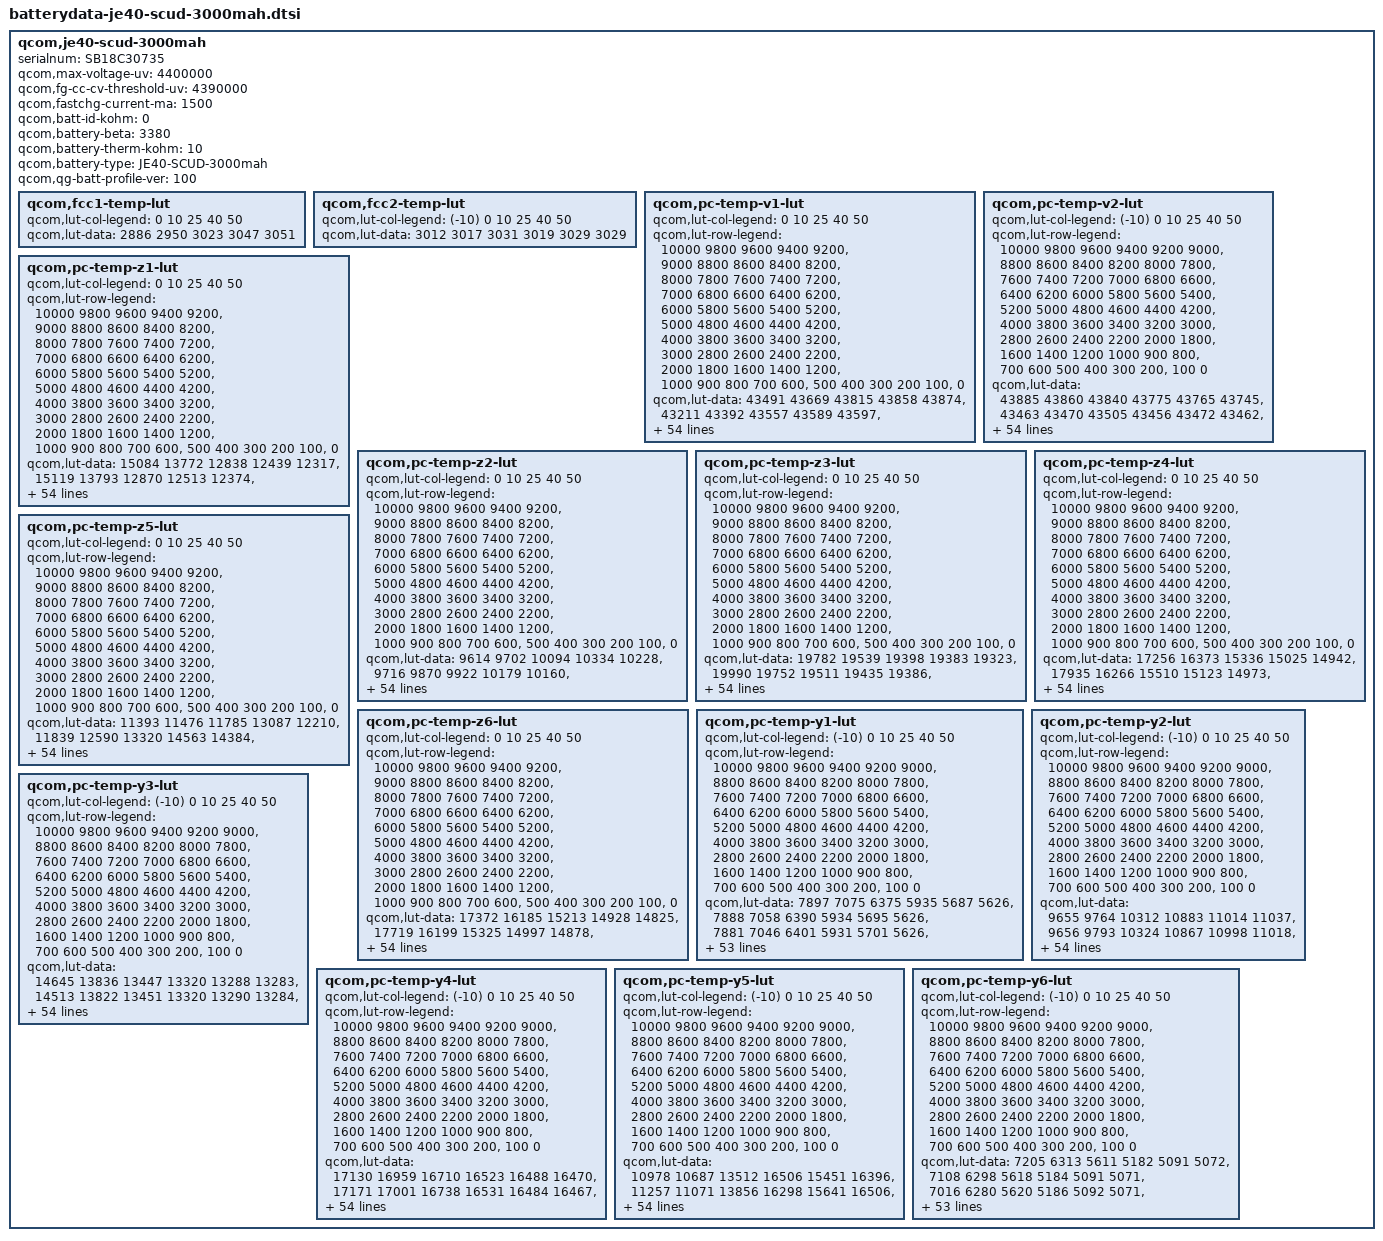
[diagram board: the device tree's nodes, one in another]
/* Copyright (c) 2018, The Linux Foundation. All rights reserved.
 *
 * This program is free software; you can redistribute it and/or modify
 * it under the terms of the GNU General Public License version 2 and
 * only version 2 as published by the Free Software Foundation.
 *
 * This program is distributed in the hope that it will be useful,
 * but WITHOUT ANY WARRANTY; without even the implied warranty of
 * MERCHANTABILITY or FITNESS FOR A PARTICULAR PURPOSE.  See the
 * GNU General Public License for more details.
 */

qcom,je40-scud-3000mah {
    serialnum = "SB18C30735";
    qcom,max-voltage-uv = <4400000>;
    qcom,fg-cc-cv-threshold-uv = <4390000>;
    qcom,fastchg-current-ma = <1500>;
    qcom,batt-id-kohm = <0>;
    qcom,battery-beta = <3380>;
    qcom,battery-therm-kohm = <10>;
    qcom,battery-type = "JE40-SCUD-3000mah";
    qcom,qg-batt-profile-ver = <100>;

	qcom,fcc1-temp-lut {
		qcom,lut-col-legend = <0 10 25 40 50>;
		qcom,lut-data = <2886 2950 3023 3047 3051>;
	};

        qcom,fcc2-temp-lut {
                qcom,lut-col-legend = <(-10) 0 10 25 40 50>;
                qcom,lut-data = <3012 3017 3031 3019 3029 3029>;
        };

	qcom,pc-temp-v1-lut {
		qcom,lut-col-legend = <0 10 25 40 50>;
		qcom,lut-row-legend = <10000 9800 9600 9400 9200>,
			<9000 8800 8600 8400 8200>,
			<8000 7800 7600 7400 7200>,
			<7000 6800 6600 6400 6200>,
			<6000 5800 5600 5400 5200>,
			<5000 4800 4600 4400 4200>,
			<4000 3800 3600 3400 3200>,
			<3000 2800 2600 2400 2200>,
			<2000 1800 1600 1400 1200>,
			<1000 900 800 700 600>,
			<500 400 300 200 100>,
			<0>;
		qcom,lut-data = <43491 43669 43815 43858 43874>,
			<43211 43392 43557 43589 43597>,
			<42956 43131 43303 43343 43353>,
			<42714 42886 43053 43104 43118>,
			<42476 42648 42808 42865 42880>,
			<42242 42411 42566 42626 42642>,
			<42016 42179 42328 42390 42407>,
			<41797 41952 42092 42154 42175>,
			<41586 41730 41861 41922 41945>,
			<41387 41514 41633 41692 41715>,
			<41203 41311 41410 41464 41486>,
			<41008 41121 41197 41242 41263>,
			<40778 40920 40993 41025 41046>,
			<40530 40689 40787 40816 40837>,
			<40306 40454 40565 40611 40631>,
			<40099 40248 40350 40413 40432>,
			<39915 40061 40169 40226 40241>,
			<39770 39895 40008 40048 40061>,
			<39648 39757 39852 39878 39888>,
			<39529 39631 39708 39725 39731>,
			<39405 39498 39554 39573 39579>,
			<39285 39357 39356 39371 39390>,
			<39168 39208 39120 39096 39139>,
			<39057 39029 38921 38875 38921>,
			<38950 38836 38752 38747 38777>,
			<38847 38680 38615 38645 38659>,
			<38747 38542 38526 38544 38547>,
			<38648 38438 38459 38447 38441>,
			<38548 38374 38394 38358 38347>,
			<38457 38327 38327 38275 38261>,
			<38391 38286 38266 38201 38186>,
			<38336 38250 38208 38136 38115>,
			<38288 38216 38156 38079 38052>,
			<38245 38186 38110 38028 37995>,
			<38208 38159 38073 37985 37949>,
			<38174 38129 38036 37943 37903>,
			<38144 38098 37999 37896 37847>,
			<38108 38062 37959 37845 37783>,
			<38058 38005 37902 37782 37711>,
			<37991 37919 37810 37702 37630>,
			<37906 37819 37704 37607 37537>,
			<37785 37700 37594 37497 37430>,
			<37648 37566 37467 37368 37304>,
			<37493 37413 37305 37211 37149>,
			<37336 37265 37157 37066 37005>,
			<37228 37159 37062 36974 36915>,
			<37189 37131 37033 36949 36890>,
			<37159 37104 37019 36932 36872>,
			<37131 37080 36999 36914 36856>,
			<37085 37041 36956 36868 36807>,
			<36901 36846 36725 36623 36557>,
			<36463 36414 36290 36192 36126>,
			<35890 35845 35715 35621 35554>,
			<35112 35069 34929 34843 34771>,
			<33863 33858 33689 33641 33583>,
			<30000 30000 30000 30000 30000>;
	};

	qcom,pc-temp-v2-lut {
		qcom,lut-col-legend = <(-10) 0 10 25 40 50>;
		qcom,lut-row-legend = <10000 9800 9600 9400 9200 9000>,
			<8800 8600 8400 8200 8000 7800>,
			<7600 7400 7200 7000 6800 6600>,
			<6400 6200 6000 5800 5600 5400>,
			<5200 5000 4800 4600 4400 4200>,
			<4000 3800 3600 3400 3200 3000>,
			<2800 2600 2400 2200 2000 1800>,
			<1600 1400 1200 1000 900 800>,
			<700 600 500 400 300 200>,
			<100 0>;
		qcom,lut-data = <43885 43860 43840 43775 43765 43745>,
			<43463 43470 43505 43456 43472 43462>,
			<43084 43119 43195 43161 43197 43193>,
			<42757 42812 42913 42894 42939 42940>,
			<42473 42543 42658 42652 42699 42701>,
			<42210 42287 42410 42416 42464 42467>,
			<41960 42031 42160 42180 42228 42232>,
			<41723 41784 41916 41946 41995 41999>,
			<41486 41548 41683 41718 41765 41771>,
			<41243 41318 41458 41492 41537 41544>,
			<41045 41122 41244 41272 41314 41322>,
			<40926 40984 41048 41057 41095 41103>,
			<40815 40852 40855 40846 40880 40888>,
			<40570 40626 40640 40638 40674 40681>,
			<40088 40263 40405 40429 40474 40479>,
			<39700 39944 40186 40232 40281 40285>,
			<39504 39725 39992 40049 40093 40099>,
			<39350 39535 39804 39876 39912 39921>,
			<39184 39346 39602 39718 39745 39753>,
			<39016 39162 39386 39577 39590 39594>,
			<38858 38986 39180 39409 39415 39417>,
			<38707 38815 38982 39167 39190 39198>,
			<38569 38655 38800 38914 38963 38979>,
			<38451 38508 38642 38732 38782 38796>,
			<38348 38372 38501 38585 38623 38634>,
			<38259 38263 38376 38460 38491 38499>,
			<38181 38181 38263 38352 38381 38388>,
			<38112 38113 38164 38256 38285 38291>,
			<38049 38054 38083 38166 38195 38199>,
			<37991 38003 38012 38084 38114 38115>,
			<37935 37956 37952 38010 38041 38039>,
			<37880 37911 37900 37941 37974 37970>,
			<37825 37867 37853 37879 37912 37907>,
			<37769 37821 37813 37824 37850 37847>,
			<37712 37774 37776 37775 37791 37789>,
			<37654 37726 37735 37725 37721 37713>,
			<37591 37676 37690 37675 37635 37602>,
			<37526 37622 37640 37620 37547 37490>,
			<37461 37558 37581 37554 37467 37403>,
			<37394 37485 37513 37478 37388 37324>,
			<37328 37400 37431 37392 37305 37241>,
			<37262 37295 37327 37292 37215 37152>,
			<37194 37185 37203 37177 37107 37046>,
			<37125 37073 37058 37038 36974 36915>,
			<37042 36974 36916 36903 36842 36784>,
			<36934 36894 36839 36847 36803 36750>,
			<36872 36852 36806 36832 36790 36738>,
			<36794 36813 36778 36812 36770 36721>,
			<36702 36763 36741 36782 36740 36692>,
			<36564 36665 36660 36692 36659 36606>,
			<36325 36429 36399 36401 36346 36284>,
			<35946 35980 35903 35904 35859 35800>,
			<35371 35339 35244 35265 35219 35163>,
			<34501 34423 34333 34393 34349 34306>,
			<33090 33098 32987 33059 33105 33114>,
			<28618 28142 29180 27710 29428 30057>;
	};

	qcom,pc-temp-z1-lut {
		qcom,lut-col-legend = <0 10 25 40 50>;
		qcom,lut-row-legend = <10000 9800 9600 9400 9200>,
			<9000 8800 8600 8400 8200>,
			<8000 7800 7600 7400 7200>,
			<7000 6800 6600 6400 6200>,
			<6000 5800 5600 5400 5200>,
			<5000 4800 4600 4400 4200>,
			<4000 3800 3600 3400 3200>,
			<3000 2800 2600 2400 2200>,
			<2000 1800 1600 1400 1200>,
			<1000 900 800 700 600>,
			<500 400 300 200 100>,
			<0>;
		qcom,lut-data = <15084 13772 12838 12439 12317>,
			<15119 13793 12870 12513 12374>,
			<15129 13810 12896 12515 12378>,
			<15132 13828 12907 12516 12381>,
			<15130 13840 12902 12513 12380>,
			<15129 13839 12894 12504 12376>,
			<15134 13834 12889 12499 12374>,
			<15154 13831 12884 12495 12374>,
			<15176 13835 12881 12493 12374>,
			<15179 13841 12884 12493 12373>,
			<15168 13837 12887 12494 12372>,
			<15149 13830 12888 12494 12371>,
			<15096 13822 12886 12492 12371>,
			<15016 13799 12885 12490 12372>,
			<14967 13770 12875 12490 12372>,
			<14936 13765 12864 12490 12374>,
			<14917 13768 12865 12491 12375>,
			<14910 13772 12873 12494 12375>,
			<14906 13784 12881 12497 12376>,
			<14906 13802 12889 12500 12379>,
			<14918 13811 12895 12502 12384>,
			<14932 13822 12898 12504 12386>,
			<14930 13832 12899 12506 12387>,
			<14917 13838 12901 12508 12388>,
			<14912 13844 12907 12511 12390>,
			<14919 13845 12914 12516 12394>,
			<14930 13844 12919 12521 12397>,
			<14949 13843 12924 12527 12401>,
			<14994 13844 12929 12532 12405>,
			<15034 13848 12934 12536 12408>,
			<15049 13856 12939 12540 12412>,
			<15061 13882 12944 12544 12416>,
			<15067 13905 12949 12551 12421>,
			<15068 13909 12954 12556 12426>,
			<15070 13911 12961 12560 12430>,
			<15082 13914 12970 12563 12434>,
			<15117 13925 12978 12568 12436>,
			<15138 13939 12985 12573 12438>,
			<15133 13957 12989 12578 12441>,
			<15123 13987 12994 12582 12445>,
			<15117 14001 13000 12586 12449>,
			<15121 13991 13007 12589 12453>,
			<15137 13984 13015 12592 12456>,
			<15194 13999 13022 12600 12462>,
			<15136 13987 13033 12605 12467>,
			<15107 14025 13025 12612 12466>,
			<15079 13982 13022 12613 12469>,
			<15099 14015 13023 12609 12470>,
			<15069 14032 13022 12620 12473>,
			<15059 14010 13043 12623 12478>,
			<15119 14025 13060 12624 12484>,
			<15164 14063 13061 12637 12495>,
			<15174 14047 13086 12659 12506>,
			<15186 14117 13114 12673 12522>,
			<15186 14117 13114 12673 12522>,
			<15186 14117 13114 12673 12522>;
	};

	qcom,pc-temp-z2-lut {
		qcom,lut-col-legend = <0 10 25 40 50>;
		qcom,lut-row-legend = <10000 9800 9600 9400 9200>,
			<9000 8800 8600 8400 8200>,
			<8000 7800 7600 7400 7200>,
			<7000 6800 6600 6400 6200>,
			<6000 5800 5600 5400 5200>,
			<5000 4800 4600 4400 4200>,
			<4000 3800 3600 3400 3200>,
			<3000 2800 2600 2400 2200>,
			<2000 1800 1600 1400 1200>,
			<1000 900 800 700 600>,
			<500 400 300 200 100>,
			<0>;
		qcom,lut-data = <9614 9702 10094 10334 10228>,
			<9716 9870 9922 10179 10160>,
			<9783 9907 10026 10221 10189>,
			<9834 9885 10081 10247 10226>,
			<9850 9860 10067 10237 10230>,
			<9860 9847 10045 10204 10229>,
			<9864 9837 10027 10189 10223>,
			<9856 9830 10009 10186 10205>,
			<9844 9825 10002 10184 10189>,
			<9836 9820 10014 10190 10196>,
			<9832 9819 10034 10203 10222>,
			<9826 9819 10047 10208 10231>,
			<9807 9820 10058 10203 10207>,
			<9776 9825 10070 10198 10183>,
			<9762 9834 10082 10204 10185>,
			<9759 9846 10095 10212 10194>,
			<9758 9866 10105 10214 10203>,
			<9765 9889 10113 10210 10215>,
			<9783 9917 10123 10207 10226>,
			<9795 9945 10139 10212 10229>,
			<9803 9960 10151 10223 10231>,
			<9807 9969 10151 10238 10237>,
			<9785 9975 10147 10263 10258>,
			<9709 9975 10139 10277 10275>,
			<9658 9972 10110 10247 10280>,
			<9650 9970 10084 10204 10283>,
			<9649 9970 10092 10212 10294>,
			<9665 9970 10114 10265 10314>,
			<9751 9975 10125 10285 10320>,
			<9826 9986 10127 10244 10266>,
			<9840 9994 10128 10194 10192>,
			<9849 9999 10125 10180 10167>,
			<9861 10005 10120 10182 10162>,
			<9876 10013 10122 10193 10162>,
			<9891 10025 10133 10221 10170>,
			<9855 10037 10145 10254 10185>,
			<9695 10049 10154 10281 10227>,
			<9598 10062 10165 10306 10315>,
			<9599 10074 10177 10325 10354>,
			<9598 10085 10192 10342 10357>,
			<9599 10097 10204 10352 10357>,
			<9607 10112 10208 10345 10351>,
			<9595 10120 10211 10334 10336>,
			<9454 10022 10220 10347 10325>,
			<9476 11168 10284 10369 10321>,
			<9664 10766 10338 10390 10339>,
			<9662 12279 10338 10351 10337>,
			<9603 11517 10427 10372 10328>,
			<9645 12481 10501 10335 10349>,
			<9559 12190 10504 10422 10480>,
			<9644 11483 10666 10454 10271>,
			<9715 11880 10639 10347 10196>,
			<9445 10848 10624 10323 10141>,
			<9373 10344 10557 10228 10092>,
			<9373 10344 10557 10228 10092>,
			<9373 10344 10557 10228 10092>;
	};

	qcom,pc-temp-z3-lut {
		qcom,lut-col-legend = <0 10 25 40 50>;
		qcom,lut-row-legend = <10000 9800 9600 9400 9200>,
			<9000 8800 8600 8400 8200>,
			<8000 7800 7600 7400 7200>,
			<7000 6800 6600 6400 6200>,
			<6000 5800 5600 5400 5200>,
			<5000 4800 4600 4400 4200>,
			<4000 3800 3600 3400 3200>,
			<3000 2800 2600 2400 2200>,
			<2000 1800 1600 1400 1200>,
			<1000 900 800 700 600>,
			<500 400 300 200 100>,
			<0>;
		qcom,lut-data = <19782 19539 19398 19383 19323>,
			<19990 19752 19511 19435 19386>,
			<20019 19844 19567 19463 19407>,
			<20030 19873 19591 19478 19421>,
			<20014 19887 19599 19481 19433>,
			<19969 19886 19603 19483 19444>,
			<19941 19880 19602 19483 19447>,
			<19934 19873 19595 19476 19437>,
			<19932 19864 19587 19467 19425>,
			<19935 19852 19575 19459 19420>,
			<19940 19841 19562 19451 19418>,
			<19946 19828 19554 19444 19413>,
			<19964 19815 19546 19437 19401>,
			<19996 19802 19540 19430 19390>,
			<20006 19787 19534 19422 19387>,
			<19988 19766 19529 19413 19385>,
			<19961 19737 19522 19409 19383>,
			<19926 19711 19513 19407 19380>,
			<19874 19684 19509 19405 19377>,
			<19837 19661 19507 19404 19372>,
			<19830 19659 19506 19404 19367>,
			<19833 19670 19515 19408 19368>,
			<19817 19686 19541 19426 19377>,
			<19788 19712 19551 19437 19384>,
			<19774 19743 19540 19417 19371>,
			<19774 19752 19527 19390 19352>,
			<19773 19754 19521 19391 19358>,
			<19790 19754 19517 19415 19404>,
			<19905 19750 19516 19433 19431>,
			<19999 19742 19526 19445 19426>,
			<19995 19734 19537 19454 19416>,
			<19973 19726 19541 19453 19410>,
			<19948 19716 19544 19446 19404>,
			<19925 19704 19543 19439 19398>,
			<19897 19692 19537 19432 19388>,
			<19829 19680 19531 19426 19379>,
			<19675 19666 19525 19423 19379>,
			<19574 19656 19519 19421 19382>,
			<19487 19656 19516 19418 19382>,
			<19355 19658 19514 19413 19381>,
			<19318 19659 19512 19409 19378>,
			<19317 19651 19505 19406 19375>,
			<19314 19630 19496 19403 19371>,
			<19279 19483 19492 19400 19369>,
			<19272 19419 19476 19394 19366>,
			<19267 19391 19453 19385 19356>,
			<19266 19289 19456 19376 19351>,
			<19267 19282 19419 19376 19351>,
			<19267 19279 19406 19376 19341>,
			<19268 19277 19402 19361 19328>,
			<19267 19285 19367 19356 19362>,
			<19267 19285 19368 19369 19375>,
			<19273 19281 19351 19372 19374>,
			<19276 19288 19347 19382 19380>,
			<19276 19288 19347 19382 19380>,
			<19276 19288 19347 19382 19380>;
	};

	qcom,pc-temp-z4-lut {
		qcom,lut-col-legend = <0 10 25 40 50>;
		qcom,lut-row-legend = <10000 9800 9600 9400 9200>,
			<9000 8800 8600 8400 8200>,
			<8000 7800 7600 7400 7200>,
			<7000 6800 6600 6400 6200>,
			<6000 5800 5600 5400 5200>,
			<5000 4800 4600 4400 4200>,
			<4000 3800 3600 3400 3200>,
			<3000 2800 2600 2400 2200>,
			<2000 1800 1600 1400 1200>,
			<1000 900 800 700 600>,
			<500 400 300 200 100>,
			<0>;
		qcom,lut-data = <17256 16373 15336 15025 14942>,
			<17935 16266 15510 15123 14973>,
			<17575 16104 15354 15066 14953>,
			<17113 15835 15205 14985 14916>,
			<16801 15563 15102 14933 14882>,
			<16537 15398 15016 14891 14846>,
			<16314 15273 14956 14855 14817>,
			<16126 15177 14910 14821 14797>,
			<15964 15102 14873 14795 14781>,
			<15825 15041 14841 14783 14768>,
			<15702 14990 14816 14774 14756>,
			<15599 14946 14800 14766 14750>,
			<15513 14912 14788 14757 14747>,
			<15442 14885 14781 14750 14744>,
			<15391 14867 14778 14744 14736>,
			<15352 14863 14775 14739 14724>,
			<15324 14863 14766 14733 14714>,
			<15303 14862 14747 14723 14705>,
			<15286 14857 14733 14713 14698>,
			<15266 14850 14725 14705 14694>,
			<15227 14839 14719 14698 14690>,
			<15182 14816 14738 14717 14702>,
			<15170 14798 14797 14816 14788>,
			<15179 14811 14847 14883 14856>,
			<15182 14850 14894 14895 14872>,
			<15173 14868 14926 14902 14881>,
			<15158 14898 14916 14891 14868>,
			<15122 14919 14885 14841 14797>,
			<14984 14909 14853 14796 14744>,
			<14875 14883 14819 14763 14730>,
			<14870 14860 14789 14736 14721>,
			<14866 14839 14770 14725 14713>,
			<14863 14821 14755 14718 14705>,
			<14863 14806 14745 14714 14702>,
			<14863 14794 14740 14712 14702>,
			<14904 14784 14735 14711 14702>,
			<15050 14777 14731 14713 14706>,
			<15137 14770 14727 14720 14716>,
			<15204 14763 14728 14726 14722>,
			<15324 14755 14737 14732 14725>,
			<15351 14751 14745 14736 14727>,
			<15329 14749 14736 14729 14722>,
			<15312 14753 14724 14718 14713>,
			<15296 14894 14721 14721 14717>,
			<15160 14885 14708 14714 14714>,
			<15118 14869 14692 14693 14695>,
			<15110 14974 14677 14686 14687>,
			<15103 14974 14701 14667 14666>,
			<15098 14972 14706 14650 14654>,
			<15091 14968 14707 14666 14666>,
			<15093 14968 14768 14704 14664>,
			<15123 14988 14776 14695 14657>,
			<15137 15006 14801 14696 14663>,
			<15172 15021 14814 14690 14660>,
			<15172 15021 14814 14690 14660>,
			<15172 15021 14814 14690 14660>;
	};

	qcom,pc-temp-z5-lut {
		qcom,lut-col-legend = <0 10 25 40 50>;
		qcom,lut-row-legend = <10000 9800 9600 9400 9200>,
			<9000 8800 8600 8400 8200>,
			<8000 7800 7600 7400 7200>,
			<7000 6800 6600 6400 6200>,
			<6000 5800 5600 5400 5200>,
			<5000 4800 4600 4400 4200>,
			<4000 3800 3600 3400 3200>,
			<3000 2800 2600 2400 2200>,
			<2000 1800 1600 1400 1200>,
			<1000 900 800 700 600>,
			<500 400 300 200 100>,
			<0>;
		qcom,lut-data = <11393 11476 11785 13087 12210>,
			<11839 12590 13320 14563 14384>,
			<12068 13303 14230 15489 15113>,
			<12249 13721 14916 16115 15721>,
			<12409 14053 15484 16482 16486>,
			<12554 14388 15941 16731 17413>,
			<12697 14699 16297 16972 17764>,
			<12850 15016 16591 17277 17593>,
			<13001 15341 16904 17532 17403>,
			<13137 15687 17467 17684 17572>,
			<13281 16076 17989 17820 18092>,
			<13445 16521 18180 17858 18252>,
			<13700 17038 18434 17878 17657>,
			<13991 17844 18622 17894 17088>,
			<14063 18538 18779 17831 17300>,
			<13962 18371 18988 17767 17987>,
			<13810 17448 19271 17959 18704>,
			<13573 16755 19690 18513 19579>,
			<13183 16354 20275 19232 20217>,
			<12890 16018 21170 19988 20149>,
			<13136 16185 22645 20989 19860>,
			<13807 17915 27977 23093 20261>,
			<14445 20614 38463 27797 21544>,
			<15136 26653 41763 30343 22343>,
			<15986 34836 34043 24582 19403>,
			<16955 37761 25307 16589 14737>,
			<17973 37163 22163 15642 14472>,
			<19508 35604 20157 16535 17402>,
			<24043 33675 19776 17617 19652>,
			<27617 31187 21251 19915 20381>,
			<27470 29351 23359 22834 20976>,
			<26419 28018 25859 25002 22196>,
			<25211 26832 29056 27020 24487>,
			<23596 25622 30816 28308 25591>,
			<21680 24429 31852 29182 25055>,
			<19634 23543 32418 29691 24401>,
			<16849 22767 32187 29542 24577>,
			<15067 22271 31489 28896 25000>,
			<13514 23037 30957 27881 25080>,
			<11445 25505 30164 25183 23575>,
			<10885 26638 29066 22618 21629>,
			<10922 25157 27028 21632 20557>,
			<10939 23206 25058 21041 19693>,
			<10869 18221 24688 19935 18867>,
			<11142 16740 24208 19906 18398>,
			<11156 15172 22879 19738 17727>,
			<11152 11383 24273 18894 17477>,
			<11146 11298 17061 20436 19072>,
			<11143 11260 15737 21690 18399>,
			<11163 11262 15941 18170 15883>,
			<11190 11369 13376 15075 18236>,
			<11159 11289 13096 15675 19740>,
			<11118 11176 12476 15420 18526>,
			<11029 11132 12266 16028 19218>,
			<11029 11132 12266 16028 19218>,
			<11029 11132 12266 16028 19218>;
	};

	qcom,pc-temp-z6-lut {
		qcom,lut-col-legend = <0 10 25 40 50>;
		qcom,lut-row-legend = <10000 9800 9600 9400 9200>,
			<9000 8800 8600 8400 8200>,
			<8000 7800 7600 7400 7200>,
			<7000 6800 6600 6400 6200>,
			<6000 5800 5600 5400 5200>,
			<5000 4800 4600 4400 4200>,
			<4000 3800 3600 3400 3200>,
			<3000 2800 2600 2400 2200>,
			<2000 1800 1600 1400 1200>,
			<1000 900 800 700 600>,
			<500 400 300 200 100>,
			<0>;
		qcom,lut-data = <17372 16185 15213 14928 14825>,
			<17719 16199 15325 14997 14878>,
			<17526 16168 15281 14983 14876>,
			<17274 16041 15233 14961 14872>,
			<17085 15889 15188 14942 14866>,
			<16912 15795 15145 14923 14856>,
			<16773 15721 15111 14904 14844>,
			<16662 15660 15084 14885 14830>,
			<16570 15611 15060 14868 14817>,
			<16495 15570 15037 14858 14808>,
			<16432 15534 15018 14850 14802>,
			<16376 15504 15006 14842 14795>,
			<16324 15474 14998 14834 14788>,
			<16277 15440 14990 14827 14781>,
			<16235 15411 14983 14820 14774>,
			<16196 15394 14976 14813 14769>,
			<16159 15381 14967 14807 14763>,
			<16124 15369 14957 14802 14758>,
			<16088 15357 14951 14797 14754>,
			<16059 15347 14948 14794 14749>,
			<16034 15345 14947 14791 14746>,
			<16015 15346 14961 14802 14752>,
			<16004 15348 15002 14856 14796>,
			<15996 15366 15028 14889 14827>,
			<15992 15402 15044 14885 14826>,
			<15990 15421 15054 14877 14824>,
			<15989 15437 15049 14870 14820>,
			<15991 15447 15036 14863 14815>,
			<16000 15442 15025 14856 14808>,
			<16006 15430 15017 14850 14801>,
			<16004 15419 15011 14844 14792>,
			<15995 15408 15007 14838 14786>,
			<15986 15398 15003 14832 14780>,
			<15977 15389 15000 14827 14775>,
			<15969 15381 14997 14823 14770>,
			<15961 15376 14994 14820 14766>,
			<15953 15372 14991 14821 14767>,
			<15946 15370 14989 14824 14773>,
			<15941 15371 14989 14825 14776>,
			<15936 15378 14997 14826 14777>,
			<15933 15382 15002 14827 14777>,
			<15933 15383 14998 14824 14774>,
			<15931 15383 14991 14819 14768>,
			<15918 15379 14993 14819 14770>,
			<15860 15354 14985 14815 14768>,
			<15847 15338 14971 14802 14755>,
			<15842 15334 14968 14795 14749>,
			<15842 15332 14961 14788 14741>,
			<15844 15332 14958 14781 14730>,
			<15847 15337 14960 14782 14730>,
			<15865 15350 14973 14797 14748>,
			<15887 15370 14984 14803 14755>,
			<15913 15389 14994 14809 14759>,
			<15960 15425 15011 14818 14766>,
			<15960 15425 15011 14818 14766>,
			<15960 15425 15011 14818 14766>;
	};

	qcom,pc-temp-y1-lut {
		qcom,lut-col-legend = <(-10) 0 10 25 40 50>;
		qcom,lut-row-legend = <10000 9800 9600 9400 9200 9000>,
			<8800 8600 8400 8200 8000 7800>,
			<7600 7400 7200 7000 6800 6600>,
			<6400 6200 6000 5800 5600 5400>,
			<5200 5000 4800 4600 4400 4200>,
			<4000 3800 3600 3400 3200 3000>,
			<2800 2600 2400 2200 2000 1800>,
			<1600 1400 1200 1000 900 800>,
			<700 600 500 400 300 200>,
			<100 0>;
		qcom,lut-data = <7897 7075 6375 5935 5687 5626>,
			<7888 7058 6390 5934 5695 5626>,
			<7881 7046 6401 5931 5701 5626>,
			<7875 7038 6409 5927 5706 5626>,
			<7871 7034 6413 5923 5708 5626>,
			<7868 7031 6415 5921 5709 5625>,
			<7868 7033 6411 5919 5707 5624>,
			<7869 7038 6406 5917 5704 5622>,
			<7865 7042 6406 5918 5703 5621>,
			<7856 7047 6408 5923 5703 5620>,
			<7852 7048 6410 5926 5702 5620>,
			<7885 7040 6411 5924 5702 5618>,
			<7932 7030 6411 5919 5700 5616>,
			<7940 7029 6412 5917 5699 5616>,
			<7931 7035 6415 5918 5696 5617>,
			<7926 7041 6419 5918 5695 5617>,
			<7917 7051 6427 5922 5696 5617>,
			<7906 7059 6435 5925 5698 5617>,
			<7908 7058 6435 5926 5698 5617>,
			<7925 7050 6430 5926 5697 5618>,
			<7935 7045 6428 5926 5697 5619>,
			<7928 7046 6431 5930 5699 5619>,
			<7918 7050 6433 5936 5702 5619>,
			<7917 7051 6433 5937 5702 5620>,
			<7920 7054 6431 5936 5700 5621>,
			<7918 7053 6431 5935 5701 5623>,
			<7906 7047 6432 5936 5704 5626>,
			<7891 7041 6433 5938 5708 5628>,
			<7882 7042 6433 5940 5711 5630>,
			<7872 7049 6432 5945 5714 5632>,
			<7868 7056 6431 5949 5717 5634>,
			<7903 7059 6430 5952 5720 5636>,
			<7946 7060 6429 5955 5724 5639>,
			<7944 7058 6429 5955 5727 5642>,
			<7919 7051 6430 5955 5731 5644>,
			<7898 7044 6430 5956 5734 5646>,
			<7883 7038 6430 5958 5737 5648>,
			<7871 7034 6431 5961 5739 5650>,
			<7876 7035 6432 5964 5742 5652>,
			<7894 7038 6435 5968 5744 5655>,
			<7908 7040 6438 5974 5746 5658>,
			<7910 7039 6454 5983 5746 5659>,
			<7913 7044 6458 5987 5747 5661>,
			<7939 7075 6453 5986 5751 5664>,
			<7954 7092 6454 5988 5755 5672>,
			<7971 7105 6484 6001 5763 5673>,
			<8024 7104 6471 6005 5771 5675>,
			<8022 7123 6475 6005 5763 5675>,
			<8023 7137 6472 6000 5766 5676>,
			<8004 7145 6508 5997 5768 5674>,
			<8029 7149 6493 6016 5770 5678>,
			<8050 7166 6518 6029 5784 5685>,
			<8114 7187 6540 6040 5791 5695>,
			<8293 7215 6599 6074 5808 5706>,
			<8293 7215 6599 6074 5808 5706>,
			<8293 7215 6599 6074 5808 5706>;
	};

	qcom,pc-temp-y2-lut {
		qcom,lut-col-legend = <(-10) 0 10 25 40 50>;
		qcom,lut-row-legend = <10000 9800 9600 9400 9200 9000>,
			<8800 8600 8400 8200 8000 7800>,
			<7600 7400 7200 7000 6800 6600>,
			<6400 6200 6000 5800 5600 5400>,
			<5200 5000 4800 4600 4400 4200>,
			<4000 3800 3600 3400 3200 3000>,
			<2800 2600 2400 2200 2000 1800>,
			<1600 1400 1200 1000 900 800>,
			<700 600 500 400 300 200>,
			<100 0>;
		qcom,lut-data = <9655 9764 10312 10883 11014 11037>,
			<9656 9793 10324 10867 10998 11018>,
			<9658 9825 10347 10848 10973 10981>,
			<9659 9855 10372 10827 10946 10939>,
			<9661 9880 10391 10807 10924 10903>,
			<9662 9897 10396 10789 10916 10889>,
			<9664 9906 10389 10772 10900 10876>,
			<9666 9914 10382 10754 10877 10859>,
			<9668 9925 10388 10736 10871 10860>,
			<9672 9941 10410 10715 10862 10869>,
			<9680 9964 10434 10702 10857 10873>,
			<9813 10025 10456 10695 10849 10863>,
			<9992 10088 10478 10692 10839 10848>,
			<9974 10090 10506 10696 10840 10843>,
			<9779 10064 10558 10719 10843 10842>,
			<9668 10049 10597 10745 10847 10844>,
			<9666 10062 10630 10766 10868 10868>,
			<9665 10084 10658 10790 10903 10907>,
			<9664 10100 10666 10831 10956 10950>,
			<9664 10115 10670 10897 11033 11002>,
			<9664 10123 10676 10925 11062 11022>,
			<9663 10127 10696 10890 11028 11012>,
			<9662 10129 10718 10848 10987 10999>,
			<9661 10064 10724 10850 10977 10986>,
			<9661 9840 10717 10877 10975 10956>,
			<9661 9715 10685 10898 10976 10947>,
			<9661 9690 10467 10915 10975 10979>,
			<9660 9677 10257 10929 10976 11018>,
			<9660 9674 10240 10932 10993 11035>,
			<9660 9674 10237 10933 11032 11047>,
			<9659 9672 10234 10934 11065 11064>,
			<9659 9670 10230 10937 11094 11101>,
			<9659 9667 10227 10939 11112 11132>,
			<9659 9665 10222 10939 11109 11145>,
			<9658 9664 10212 10936 11094 11157>,
			<9658 9663 10203 10929 11078 11151>,
			<9658 9661 10194 10915 11047 11083>,
			<9657 9660 10183 10899 11024 11025>,
			<9657 9659 10169 10887 11025 11026>,
			<9657 9658 10150 10875 11029 11031>,
			<9657 9657 10128 10859 11034 11026>,
			<9657 9657 10099 10833 11033 10989>,
			<9656 9656 9972 10799 11028 10975>,
			<9656 9656 9691 10756 11007 10971>,
			<9656 9655 9673 10715 10961 10951>,
			<9656 9655 9671 10607 10912 10869>,
			<9655 9655 9665 10681 10931 10878>,
			<9655 9655 9661 10644 10903 10824>,
			<9655 9655 9659 10635 10852 10828>,
			<9655 9654 9657 10617 10874 10850>,
			<9654 9654 9656 10548 10853 10840>,
			<9654 9654 9654 10472 10813 10760>,
			<9653 9653 9653 10428 10761 10710>,
			<9650 9652 9653 10376 10683 10656>,
			<9650 9652 9653 10376 10683 10656>,
			<9650 9652 9653 10376 10683 10656>;
	};

	qcom,pc-temp-y3-lut {
		qcom,lut-col-legend = <(-10) 0 10 25 40 50>;
		qcom,lut-row-legend = <10000 9800 9600 9400 9200 9000>,
			<8800 8600 8400 8200 8000 7800>,
			<7600 7400 7200 7000 6800 6600>,
			<6400 6200 6000 5800 5600 5400>,
			<5200 5000 4800 4600 4400 4200>,
			<4000 3800 3600 3400 3200 3000>,
			<2800 2600 2400 2200 2000 1800>,
			<1600 1400 1200 1000 900 800>,
			<700 600 500 400 300 200>,
			<100 0>;
		qcom,lut-data = <14645 13836 13447 13320 13288 13283>,
			<14513 13822 13451 13320 13290 13284>,
			<14384 13801 13454 13321 13291 13285>,
			<14265 13778 13456 13322 13293 13285>,
			<14161 13754 13457 13323 13294 13286>,
			<14077 13730 13456 13324 13295 13287>,
			<14015 13706 13454 13326 13297 13288>,
			<13962 13680 13452 13328 13298 13289>,
			<13901 13659 13455 13329 13299 13290>,
			<13832 13644 13465 13330 13300 13293>,
			<13787 13638 13471 13331 13300 13295>,
			<13766 13612 13454 13333 13300 13296>,
			<13754 13577 13432 13336 13301 13296>,
			<13746 13568 13429 13337 13303 13296>,
			<13717 13552 13426 13338 13307 13297>,
			<13696 13537 13425 13338 13309 13297>,
			<13687 13526 13423 13336 13307 13299>,
			<13680 13513 13419 13332 13304 13302>,
			<13677 13501 13412 13333 13304 13302>,
			<13678 13487 13402 13338 13305 13300>,
			<13678 13480 13392 13340 13305 13298>,
			<13678 13475 13384 13334 13303 13294>,
			<13677 13470 13376 13325 13299 13290>,
			<13678 13462 13370 13321 13296 13288>,
			<13684 13449 13365 13317 13293 13285>,
			<13691 13438 13359 13316 13292 13285>,
			<13702 13434 13340 13315 13292 13285>,
			<13717 13437 13323 13315 13291 13285>,
			<13736 13449 13322 13315 13291 13285>,
			<13765 13464 13322 13314 13292 13283>,
			<13795 13481 13325 13314 13292 13283>,
			<13825 13506 13335 13314 13292 13283>,
			<13858 13538 13347 13315 13293 13283>,
			<13895 13569 13356 13315 13294 13284>,
			<13937 13602 13367 13315 13295 13286>,
			<13982 13639 13377 13316 13295 13286>,
			<14031 13682 13389 13317 13294 13285>,
			<14081 13728 13403 13318 13293 13283>,
			<14131 13779 13425 13317 13292 13283>,
			<14181 13834 13455 13315 13290 13283>,
			<14237 13892 13484 13314 13290 13284>,
			<14304 13952 13512 13316 13292 13285>,
			<14375 14014 13549 13317 13292 13285>,
			<14447 14079 13599 13318 13292 13286>,
			<14539 14152 13643 13321 13292 13281>,
			<14481 14139 13654 13317 13294 13288>,
			<14588 14211 13696 13322 13296 13291>,
			<14682 14302 13754 13326 13298 13294>,
			<14791 14388 13831 13335 13303 13298>,
			<14917 14475 13913 13340 13309 13301>,
			<15065 14575 14006 13339 13300 13294>,
			<15258 14708 14159 13344 13303 13295>,
			<15696 14896 14393 13359 13309 13298>,
			<17006 15186 14600 13376 13317 13305>,
			<17006 15186 14600 13376 13317 13305>,
			<17006 15186 14600 13376 13317 13305>;
	};

	qcom,pc-temp-y4-lut {
		qcom,lut-col-legend = <(-10) 0 10 25 40 50>;
		qcom,lut-row-legend = <10000 9800 9600 9400 9200 9000>,
			<8800 8600 8400 8200 8000 7800>,
			<7600 7400 7200 7000 6800 6600>,
			<6400 6200 6000 5800 5600 5400>,
			<5200 5000 4800 4600 4400 4200>,
			<4000 3800 3600 3400 3200 3000>,
			<2800 2600 2400 2200 2000 1800>,
			<1600 1400 1200 1000 900 800>,
			<700 600 500 400 300 200>,
			<100 0>;
		qcom,lut-data = <17130 16959 16710 16523 16488 16470>,
			<17171 17001 16738 16531 16484 16467>,
			<17225 17047 16775 16539 16482 16466>,
			<17280 17091 16812 16545 16480 16465>,
			<17323 17125 16841 16550 16480 16464>,
			<17341 17142 16854 16554 16479 16465>,
			<17337 17142 16855 16554 16480 16466>,
			<17330 17138 16852 16554 16482 16467>,
			<17342 17138 16846 16557 16484 16468>,
			<17398 17142 16834 16563 16489 16468>,
			<17437 17160 16834 16569 16495 16469>,
			<17493 17280 16893 16574 16502 16473>,
			<17558 17426 16969 16580 16510 16480>,
			<17488 17397 16987 16590 16515 16487>,
			<17200 17181 16975 16609 16519 16496>,
			<17031 17025 16966 16632 16526 16505>,
			<17029 16973 16945 16662 16544 16512>,
			<17031 16936 16914 16695 16569 16521>,
			<17018 16908 16882 16722 16600 16541>,
			<16987 16877 16825 16748 16638 16577>,
			<16957 16841 16768 16756 16651 16591>,
			<16930 16790 16713 16675 16607 16569>,
			<16907 16745 16666 16568 16547 16536>,
			<16899 16736 16635 16531 16512 16507>,
			<16896 16742 16610 16512 16483 16477>,
			<16894 16751 16601 16504 16475 16467>,
			<16898 16762 16615 16503 16477 16469>,
			<16903 16772 16630 16505 16480 16472>,
			<16902 16776 16628 16508 16486 16477>,
			<16895 16778 16625 16513 16496 16488>,
			<16891 16779 16624 16517 16506 16499>,
			<16891 16775 16620 16520 16520 16512>,
			<16891 16773 16617 16523 16531 16524>,
			<16891 16775 16621 16526 16535 16534>,
			<16891 16781 16629 16531 16537 16543>,
			<16894 16786 16639 16533 16535 16541>,
			<16901 16792 16654 16533 16510 16506>,
			<16910 16799 16668 16531 16487 16476>,
			<16922 16805 16679 16528 16484 16473>,
			<16939 16812 16688 16525 16481 16472>,
			<16959 16814 16692 16525 16482 16473>,
			<16987 16799 16694 16531 16488 16481>,
			<17016 16785 16701 16537 16491 16482>,
			<17044 16776 16711 16542 16490 16477>,
			<17046 16780 16696 16528 16470 16460>,
			<16950 16760 16682 16530 16473 16464>,
			<16965 16784 16704 16537 16486 16475>,
			<16984 16809 16729 16560 16505 16496>,
			<17010 16849 16760 16587 16535 16531>,
			<17021 16899 16804 16607 16554 16545>,
			<17005 16881 16787 16585 16496 16475>,
			<16989 16834 16758 16585 16495 16473>,
			<17026 16830 16775 16621 16510 16486>,
			<17367 16870 16812 16698 16575 16545>,
			<17367 16870 16812 16698 16575 16545>,
			<17367 16870 16812 16698 16575 16545>;
	};

	qcom,pc-temp-y5-lut {
		qcom,lut-col-legend = <(-10) 0 10 25 40 50>;
		qcom,lut-row-legend = <10000 9800 9600 9400 9200 9000>,
			<8800 8600 8400 8200 8000 7800>,
			<7600 7400 7200 7000 6800 6600>,
			<6400 6200 6000 5800 5600 5400>,
			<5200 5000 4800 4600 4400 4200>,
			<4000 3800 3600 3400 3200 3000>,
			<2800 2600 2400 2200 2000 1800>,
			<1600 1400 1200 1000 900 800>,
			<700 600 500 400 300 200>,
			<100 0>;
		qcom,lut-data = <10978 10687 13512 16506 15451 16396>,
			<11257 11071 13856 16298 15641 16506>,
			<11530 11734 14340 16093 15763 16466>,
			<11790 12465 14838 15903 15832 16342>,
			<12028 13052 15225 15743 15861 16203>,
			<12237 13284 15378 15624 15868 16117>,
			<12456 13249 15351 15555 15823 16027>,
			<12631 13191 15290 15495 15720 15903>,
			<12574 13335 15390 15333 15519 15950>,
			<12183 14065 15970 14966 15043 16447>,
			<11961 14482 16201 14696 14594 16629>,
			<14073 14646 15200 14532 14177 16235>,
			<17078 14895 14009 14352 13857 15659>,
			<16941 15274 14212 14190 13903 15068>,
			<14169 16594 15618 13987 14198 14387>,
			<12488 17274 16977 13831 14328 14118>,
			<12437 16658 18218 13694 13690 14239>,
			<12479 15876 19187 13612 12935 14379>,
			<12530 15881 19493 14451 12946 14215>,
			<12578 16251 19666 17519 13347 13654>,
			<12590 16430 19772 19518 14039 13484>,
			<12389 16225 19702 20167 16594 15397>,
			<12087 15785 19520 20524 19061 17554>,
			<11920 14809 19258 20264 19033 17945>,
			<11746 12828 18900 19225 18338 18110>,
			<11617 11763 18699 18564 17744 18133>,
			<11516 11540 17037 18480 17228 17737>,
			<11446 11424 15362 18491 16807 17104>,
			<11471 11422 15047 18325 16575 16303>,
			<11589 11506 14484 17985 16393 15326>,
			<11646 11600 14074 17857 16364 15012>,
			<11705 11765 13904 18178 16668 15062>,
			<11780 11956 13897 18597 17150 15181>,
			<11817 12074 14306 18826 17897 15802>,
			<11900 12165 15049 19006 18922 17026>,
			<11920 12290 15253 19076 19344 17553>,
			<11868 12547 15190 19376 19232 17594>,
			<11810 12801 15148 19690 18920 17557>,
			<11768 12924 15305 19160 18163 17429>,
			<11712 13012 15576 17589 17003 17096>,
			<11696 13053 15582 16662 16527 16729>,
			<11727 12920 15115 16199 16384 16217>,
			<11795 12736 14298 16034 16242 16310>,
			<12067 12408 13100 15724 16022 17286>,
			<12354 12130 12607 16626 17205 15587>,
			<12437 12290 12775 15856 16833 16281>,
			<12574 12145 12471 15678 15907 16046>,
			<12667 12434 12640 15335 14848 15614>,
			<12941 12660 12896 15476 15029 15484>,
			<13134 12757 12975 15567 16172 15902>,
			<13152 12822 12964 15900 16121 17464>,
			<12903 12543 12744 16681 17989 18552>,
			<12271 12473 12770 18549 19732 19264>,
			<11056 12564 13351 19607 21449 22120>,
			<11056 12564 13351 19607 21449 22120>,
			<11056 12564 13351 19607 21449 22120>;
	};

	qcom,pc-temp-y6-lut {
		qcom,lut-col-legend = <(-10) 0 10 25 40 50>;
		qcom,lut-row-legend = <10000 9800 9600 9400 9200 9000>,
			<8800 8600 8400 8200 8000 7800>,
			<7600 7400 7200 7000 6800 6600>,
			<6400 6200 6000 5800 5600 5400>,
			<5200 5000 4800 4600 4400 4200>,
			<4000 3800 3600 3400 3200 3000>,
			<2800 2600 2400 2200 2000 1800>,
			<1600 1400 1200 1000 900 800>,
			<700 600 500 400 300 200>,
			<100 0>;
		qcom,lut-data = <7205 6313 5611 5182 5091 5072>,
			<7108 6298 5618 5184 5091 5071>,
			<7016 6280 5620 5186 5092 5071>,
			<6931 6258 5618 5187 5093 5072>,
			<6854 6233 5614 5188 5094 5072>,
			<6788 6207 5609 5189 5095 5073>,
			<6732 6176 5599 5189 5096 5073>,
			<6683 6144 5588 5189 5097 5075>,
			<6638 6118 5581 5189 5098 5076>,
			<6594 6094 5577 5190 5099 5078>,
			<6574 6084 5575 5192 5101 5080>,
			<6585 6093 5575 5194 5103 5081>,
			<6600 6106 5577 5196 5105 5083>,
			<6576 6092 5576 5200 5108 5086>,
			<6461 6024 5571 5205 5112 5088>,
			<6390 5973 5568 5211 5116 5091>,
			<6387 5955 5561 5218 5120 5094>,
			<6386 5942 5551 5225 5125 5099>,
			<6383 5929 5538 5233 5133 5105>,
			<6379 5916 5514 5244 5144 5113>,
			<6376 5903 5491 5247 5148 5116>,
			<6372 5891 5471 5220 5133 5107>,
			<6369 5881 5456 5184 5113 5094>,
			<6371 5876 5447 5171 5101 5083>,
			<6378 5872 5441 5164 5091 5073>,
			<6387 5871 5439 5161 5088 5070>,
			<6399 5882 5439 5162 5088 5071>,
			<6414 5901 5440 5163 5090 5072>,
			<6430 5918 5443 5165 5091 5074>,
			<6450 5938 5453 5168 5095 5076>,
			<6473 5960 5464 5170 5099 5079>,
			<6498 5986 5477 5173 5104 5083>,
			<6526 6015 5492 5176 5108 5087>,
			<6556 6046 5511 5180 5110 5091>,
			<6590 6080 5533 5183 5112 5095>,
			<6626 6118 5559 5186 5112 5095>,
			<6665 6161 5587 5189 5104 5084>,
			<6708 6207 5619 5191 5097 5074>,
			<6751 6257 5657 5193 5096 5074>,
			<6796 6311 5700 5195 5095 5075>,
			<6846 6363 5745 5198 5095 5075>,
			<6906 6411 5793 5206 5099 5078>,
			<6971 6460 5846 5216 5101 5079>,
			<7039 6512 5905 5226 5101 5079>,
			<7122 6578 5957 5234 5096 5072>,
			<7079 6572 5972 5231 5100 5077>,
			<7163 6636 6030 5243 5106 5083>,
			<7246 6713 6104 5258 5113 5092>,
			<7341 6792 6192 5279 5126 5105>,
			<7445 6875 6285 5298 5136 5111>,
			<7565 6950 6374 5300 5113 5086>,
			<7724 7046 6508 5321 5117 5088>,
			<8118 7200 6709 5374 5129 5095>,
			<9321 7460 6895 5443 5157 5119>,
			<9321 7460 6895 5443 5157 5119>,
			<9321 7460 6895 5443 5157 5119>;
	};

};
